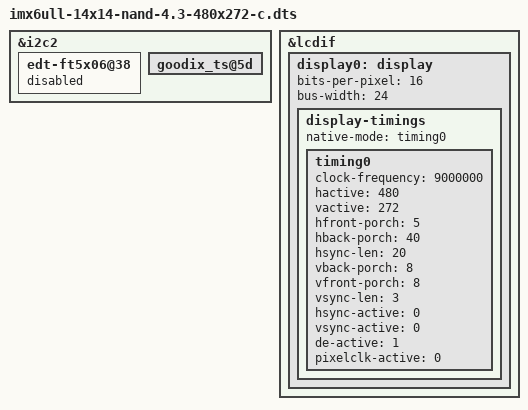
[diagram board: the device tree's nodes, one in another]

#include "imx6ull-14x14-evk-gpmi-weim.dts"

&i2c2 {
	edt-ft5x06@38 {
		status = "disabled";
	};

	goodix_ts@5d {
		status = "okay";
	};
};

&lcdif {
	display0: display {
		bits-per-pixel = <16>;
		bus-width = <24>;

		display-timings {
			native-mode = <&timing0>;
			timing0: timing0 {
			clock-frequency = <9000000>;
			hactive = <480>;
			vactive = <272>;
			hfront-porch = <5>;
			hback-porch = <40>;
			hsync-len = <20>;
			vback-porch = <8>;
			vfront-porch = <8>;
			vsync-len = <3>;

			hsync-active = <0>;
			vsync-active = <0>;
			de-active = <1>;
			pixelclk-active = <0>;
			};
		};
	};
};
